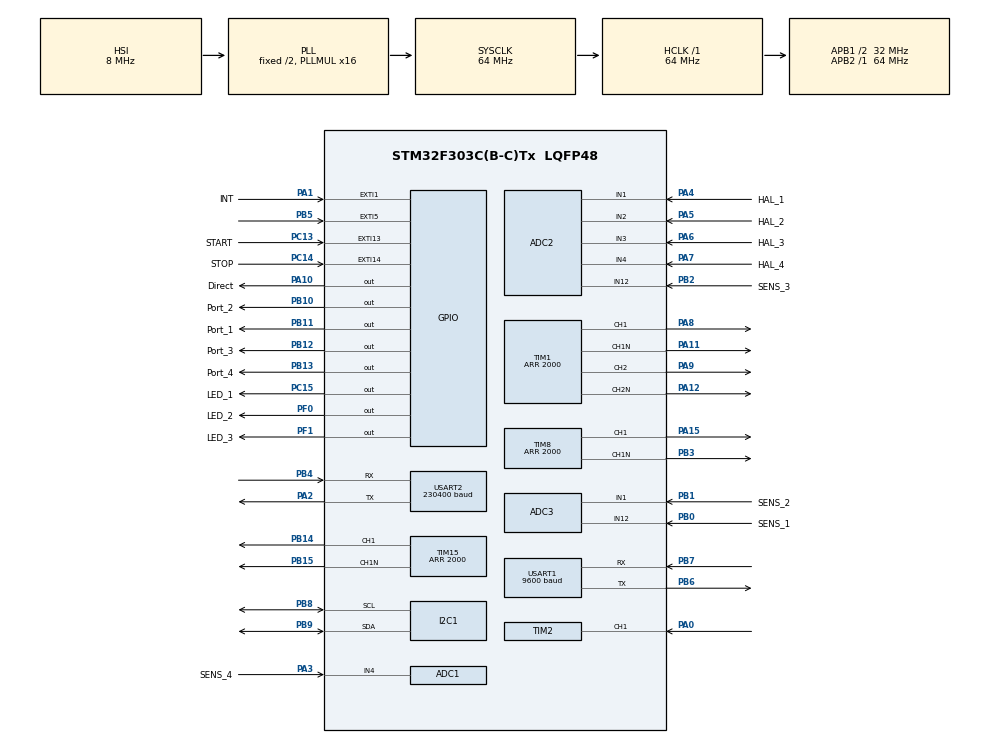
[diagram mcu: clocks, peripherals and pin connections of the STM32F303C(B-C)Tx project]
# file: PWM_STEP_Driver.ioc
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ADC1.Channel-3\#ChannelRegularConversion=ADC_CHANNEL_4
ADC1.ContinuousConvMode=DISABLE
ADC1.EnableInjectedConversion=DISABLE
ADC1.EnableRegularConversion=ENABLE
ADC1.NbrOfConversionFlag=1
ADC1.Offset-3\#ChannelRegularConversion=0
ADC1.OffsetNumber-3\#ChannelRegularConversion=ADC_OFFSET_NONE
ADC1.Rank-3\#ChannelRegularConversion=1
ADC1.SamplingTime-3\#ChannelRegularConversion=ADC_SAMPLETIME_4CYCLES_5
ADC1.SamplingTimeOPAMP-3\#ChannelRegularConversion=ADC_SAMPLETIME_61CYCLES_5
ADC1.master=1
ADC2.Channel-0\#ChannelRegularConversion=ADC_CHANNEL_1
ADC2.Channel-1\#ChannelRegularConversion=ADC_CHANNEL_2
ADC2.Channel-2\#ChannelRegularConversion=ADC_CHANNEL_3
ADC2.Channel-3\#ChannelRegularConversion=ADC_CHANNEL_4
ADC2.Channel-5\#ChannelRegularConversion=ADC_CHANNEL_12
ADC2.ContinuousConvMode=ENABLE
ADC2.EnableInjectedConversion=DISABLE
ADC2.NbrOfConversion=5
ADC2.NbrOfConversionFlag=1
ADC2.Offset-0\#ChannelRegularConversion=0
ADC2.Offset-1\#ChannelRegularConversion=0
ADC2.Offset-2\#ChannelRegularConversion=0
ADC2.Offset-3\#ChannelRegularConversion=0
ADC2.Offset-5\#ChannelRegularConversion=0
ADC2.OffsetNumber-0\#ChannelRegularConversion=ADC_OFFSET_NONE
ADC2.OffsetNumber-1\#ChannelRegularConversion=ADC_OFFSET_NONE
ADC2.OffsetNumber-2\#ChannelRegularConversion=ADC_OFFSET_NONE
ADC2.OffsetNumber-3\#ChannelRegularConversion=ADC_OFFSET_NONE
ADC2.OffsetNumber-5\#ChannelRegularConversion=ADC_OFFSET_NONE
ADC2.Rank-0\#ChannelRegularConversion=1
ADC2.Rank-1\#ChannelRegularConversion=2
ADC2.Rank-2\#ChannelRegularConversion=3
ADC2.Rank-3\#ChannelRegularConversion=4
ADC2.Rank-5\#ChannelRegularConversion=5
ADC2.SamplingTime-0\#ChannelRegularConversion=ADC_SAMPLETIME_4CYCLES_5
ADC2.SamplingTime-1\#ChannelRegularConversion=ADC_SAMPLETIME_4CYCLES_5
ADC2.SamplingTime-2\#ChannelRegularConversion=ADC_SAMPLETIME_4CYCLES_5
ADC2.SamplingTime-3\#ChannelRegularConversion=ADC_SAMPLETIME_4CYCLES_5
ADC2.SamplingTime-5\#ChannelRegularConversion=ADC_SAMPLETIME_4CYCLES_5
ADC2.SequencerNbRanks=5
ADC3.Channel-6\#ChannelRegularConversion=ADC_CHANNEL_1
ADC3.DiscontinuousConvMode=DISABLE
ADC3.EnableInjectedConversion=DISABLE
ADC3.EnableRegularConversion=ENABLE
ADC3.NbrOfConversion=1
ADC3.NbrOfConversionFlag=1
ADC3.Offset-6\#ChannelRegularConversion=0
ADC3.OffsetNumber-6\#ChannelRegularConversion=ADC_OFFSET_NONE
ADC3.Rank-6\#ChannelRegularConversion=1
ADC3.Rank1_Channel=ADC_CHANNEL_1
ADC3.Rank2_Channel=ADC_CHANNEL_1
ADC3.SamplingTime-6\#ChannelRegularConversion=ADC_SAMPLETIME_4CYCLES_5
ADC3.SequencerNbRanks=0
ADC3.master=1
Dma.ADC2.0.Direction=DMA_PERIPH_TO_MEMORY
Dma.ADC2.0.Instance=DMA2_Channel1
Dma.ADC2.0.MemDataAlignment=DMA_MDATAALIGN_HALFWORD
Dma.ADC2.0.MemInc=DMA_MINC_ENABLE
Dma.ADC2.0.Mode=DMA_NORMAL
Dma.ADC2.0.PeriphDataAlignment=DMA_PDATAALIGN_HALFWORD
Dma.ADC2.0.PeriphInc=DMA_PINC_DISABLE
Dma.ADC2.0.Priority=DMA_PRIORITY_LOW
Dma.Request0=ADC2
Dma.Request1=USART2_RX
Dma.Request2=USART2_TX
Dma.USART2_RX.1.Direction=DMA_PERIPH_TO_MEMORY
Dma.USART2_RX.1.Instance=DMA1_Channel6
Dma.USART2_RX.1.MemDataAlignment=DMA_MDATAALIGN_BYTE
Dma.USART2_RX.1.MemInc=DMA_MINC_ENABLE
Dma.USART2_RX.1.Mode=DMA_NORMAL
Dma.USART2_RX.1.PeriphDataAlignment=DMA_PDATAALIGN_BYTE
Dma.USART2_RX.1.PeriphInc=DMA_PINC_DISABLE
Dma.USART2_RX.1.Priority=DMA_PRIORITY_HIGH
Dma.USART2_TX.2.Direction=DMA_MEMORY_TO_PERIPH
Dma.USART2_TX.2.Instance=DMA1_Channel7
Dma.USART2_TX.2.MemDataAlignment=DMA_MDATAALIGN_BYTE
Dma.USART2_TX.2.MemInc=DMA_MINC_ENABLE
Dma.USART2_TX.2.Mode=DMA_NORMAL
Dma.USART2_TX.2.PeriphDataAlignment=DMA_PDATAALIGN_BYTE
Dma.USART2_TX.2.PeriphInc=DMA_PINC_DISABLE
Dma.USART2_TX.2.Priority=DMA_PRIORITY_LOW
I2C1.OwnAddress=0x12
Mcu.Family=STM32F3
Mcu.Name=STM32F303C(B-C)Tx
Mcu.Package=LQFP48
NVIC.ADC1_2_IRQn=true\:2\:0\:true\:false\:true\:true\:true\:true
NVIC.DMA1_Channel6_IRQn=true\:0\:0\:false\:false\:true\:false\:true\:true
NVIC.DMA1_Channel7_IRQn=true\:0\:0\:false\:false\:true\:false\:true\:true
NVIC.DMA2_Channel1_IRQn=true\:0\:0\:false\:false\:true\:false\:true\:true
NVIC.EXTI15_10_IRQn=true\:3\:0\:true\:false\:true\:true\:true\:true
NVIC.EXTI1_IRQn=true\:0\:0\:false\:false\:true\:true\:true\:true
NVIC.EXTI9_5_IRQn=true\:1\:0\:true\:false\:true\:true\:true\:true
NVIC.I2C1_ER_IRQn=true\:0\:0\:false\:false\:true\:true\:true\:true
NVIC.I2C1_EV_IRQn=true\:0\:0\:false\:false\:true\:true\:true\:true
NVIC.PriorityGroup=NVIC_PRIORITYGROUP_4
NVIC.RCC_IRQn=true\:0\:0\:false\:false\:true\:true\:false\:true
NVIC.TIM2_IRQn=true\:0\:0\:false\:false\:true\:true\:true\:true
NVIC.USART2_IRQn=true\:1\:0\:true\:false\:true\:true\:true\:true
PA0.Signal=S_TIM2_CH1_ETR
PA1.GPIO_Label=INT
PA1.GPIO_ModeDefaultEXTI=GPIO_MODE_IT_RISING_FALLING
PA1.Signal=GPXTI1
PA10.GPIO_Label=Direct
PA10.Signal=GPIO_Output
PA11.Mode=PWM Generation1 CH1 CH1N
PA11.Signal=TIM1_CH1N
PA12.Mode=PWM Generation2 CH2 CH2N
PA12.Signal=TIM1_CH2N
PA13.Mode=Serial_Wire
PA13.Signal=SYS_JTMS-SWDIO
PA14.Mode=Serial_Wire
PA14.Signal=SYS_JTCK-SWCLK
PA15.Signal=S_TIM8_CH1
PA2.Mode=Asynchronous
PA2.Signal=USART2_TX
PA3.GPIO_Label=SENS_4
PA3.Mode=IN4-Single-Ended
PA3.Signal=ADC1_IN4
PA4.GPIO_Label=HAL_1
PA4.Mode=IN1-Single-Ended
PA4.Signal=ADC2_IN1
PA5.GPIO_Label=HAL_2
PA5.Mode=IN2-Single-Ended
PA5.Signal=ADC2_IN2
PA6.GPIO_Label=HAL_3
PA6.Mode=IN3-Single-Ended
PA6.Signal=ADC2_IN3
PA7.GPIO_Label=HAL_4
PA7.Mode=IN4-Single-Ended
PA7.Signal=ADC2_IN4
PA8.Signal=S_TIM1_CH1
PA9.Signal=S_TIM1_CH2
PB0.GPIO_Label=SENS_1
PB0.Mode=IN12-Single-Ended
PB0.Signal=ADC3_IN12
PB1.GPIO_Label=SENS_2
PB1.Mode=IN1-Single-Ended
PB1.Signal=ADC3_IN1
PB10.GPIO_Label=Port_2
PB10.Signal=GPIO_Output
PB11.GPIO_Label=Port_1
PB11.Signal=GPIO_Output
PB12.GPIO_Label=Port_3
PB12.Signal=GPIO_Output
PB13.GPIO_Label=Port_4
PB13.Signal=GPIO_Output
PB14.Signal=S_TIM15_CH1
PB15.Mode=PWM Generation1 CH1 CH1N
PB15.Signal=TIM15_CH1N
PB2.GPIO_Label=SENS_3
PB2.Mode=IN12-Single-Ended
PB2.Signal=ADC2_IN12
PB3.Mode=PWM Generation1 CH1 CH1N
PB3.Signal=TIM8_CH1N
PB4.Mode=Asynchronous
PB4.Signal=USART2_RX
PB5.GPIO_ModeDefaultEXTI=GPIO_MODE_IT_RISING_FALLING
PB5.Signal=GPXTI5
PB6.Mode=Asynchronous
PB6.Signal=USART1_TX
PB7.Mode=Asynchronous
PB7.Signal=USART1_RX
PB8.GPIO_Pu=GPIO_PULLUP
PB8.Mode=I2C
PB8.Signal=I2C1_SCL
PB9.GPIO_Pu=GPIO_PULLUP
PB9.Mode=I2C
PB9.Signal=I2C1_SDA
PC13.GPIO_Label=START
PC13.GPIO_ModeDefaultEXTI=GPIO_MODE_IT_RISING_FALLING
PC13.Signal=GPXTI13
PC14-OSC32_IN.GPIO_Label=STOP
PC14-OSC32_IN.GPIO_ModeDefaultEXTI=GPIO_MODE_IT_RISING_FALLING
PC14-OSC32_IN.Signal=GPXTI14
PC15-OSC32_OUT.GPIO_Label=LED_1
PC15-OSC32_OUT.PinState=GPIO_PIN_RESET
PC15-OSC32_OUT.Signal=GPIO_Output
PF0-OSC_IN.GPIO_Label=LED_2
PF0-OSC_IN.PinState=GPIO_PIN_RESET
PF0-OSC_IN.Signal=GPIO_Output
PF1-OSC_OUT.GPIO_Label=LED_3
PF1-OSC_OUT.PinState=GPIO_PIN_RESET
PF1-OSC_OUT.Signal=GPIO_Output
ProjectManager.HeapSize=0x200
ProjectManager.StackSize=0x400
ProjectManager.TargetToolchain=STM32CubeIDE
RCC.AHBFreq_Value=64000000
RCC.APB1CLKDivider=RCC_HCLK_DIV2
RCC.APB1Freq_Value=32000000
RCC.APB1TimFreq_Value=64000000
RCC.APB2Freq_Value=64000000
RCC.APB2TimFreq_Value=64000000
RCC.CortexFreq_Value=64000000
RCC.HCLKFreq_Value=64000000
RCC.HSE_VALUE=8000000
RCC.HSI_VALUE=8000000
RCC.LSE_VALUE=32768
RCC.PLLMUL=RCC_PLL_MUL16
RCC.SYSCLKFreq_VALUE=64000000
RCC.SYSCLKSourceVirtual=RCC_SYSCLKSOURCE_PLLCLK
RCC.USBFreq_Value=64000000
RTC.Hours=9
RTC.Month=RTC_MONTH_JUNE
RTC.SynchPrediv=311
SH.S_TIM15_CH1.0=TIM15_CH1,PWM Generation1 CH1 CH1N
SH.S_TIM1_CH1.0=TIM1_CH1,PWM Generation1 CH1 CH1N
SH.S_TIM1_CH2.0=TIM1_CH2,PWM Generation2 CH2 CH2N
SH.S_TIM2_CH1_ETR.0=TIM2_CH1,Input_Capture1_from_TI1
SH.S_TIM8_CH1.0=TIM8_CH1,PWM Generation1 CH1 CH1N
TIM1.AutoReloadPreload=TIM_AUTORELOAD_PRELOAD_ENABLE
TIM1.Channel-PWM\ Generation1\ CH1\ CH1N=TIM_CHANNEL_1
TIM1.Channel-PWM\ Generation2\ CH2\ CH2N=TIM_CHANNEL_2
TIM1.DeadTime=100
TIM1.OCFastMode_PWM-PWM\ Generation1\ CH1\ CH1N=TIM_OCFAST_ENABLE
TIM1.OCFastMode_PWM-PWM\ Generation2\ CH2\ CH2N=TIM_OCFAST_ENABLE
TIM1.OCMode_PWM-PWM\ Generation1\ CH1\ CH1N=TIM_OCMODE_PWM1
TIM1.OCMode_PWM-PWM\ Generation2\ CH2\ CH2N=TIM_OCMODE_PWM1
TIM1.Period=2000
TIM1.Pulse-PWM\ Generation1\ CH1\ CH1N=1000
TIM1.Pulse-PWM\ Generation2\ CH2\ CH2N=1000
TIM1.RepetitionCounter=0
TIM15.AutoReloadPreload=TIM_AUTORELOAD_PRELOAD_ENABLE
TIM15.Channel-PWM\ Generation1\ CH1\ CH1N=TIM_CHANNEL_1
TIM15.DeadTime=100
TIM15.Period=2000
TIM15.Pulse-PWM\ Generation1\ CH1\ CH1N=1000
TIM2.Channel-Input_Capture1_from_TI1=TIM_CHANNEL_1
TIM2.Channel-Input_Capture2_from_TI1_63=TIM_CHANNEL_2
TIM2.ICFilter_CH1=12
TIM2.ICPolarity_CH2=TIM_INPUTCHANNELPOLARITY_FALLING
TIM2.Period=64000000
TIM2.Prescaler=0
TIM3.AutoReloadPreload=TIM_AUTORELOAD_PRELOAD_ENABLE
TIM3.TIM_MasterSlaveMode=TIM_MASTERSLAVEMODE_DISABLE
TIM8.AutoReloadPreload=TIM_AUTORELOAD_PRELOAD_ENABLE
TIM8.Channel-PWM\ Generation1\ CH1\ CH1N=TIM_CHANNEL_1
TIM8.DeadTime=100
TIM8.OCMode_PWM-PWM\ Generation1\ CH1\ CH1N=TIM_OCMODE_PWM1
TIM8.Period=2000
TIM8.Pulse-PWM\ Generation1\ CH1\ CH1N=1000
TIM8.RepetitionCounter=0
USART1.BaudRate=9600
USART1.VirtualMode-Asynchronous=VM_ASYNC
USART2.BaudRate=230400
USART2.VirtualMode-Asynchronous=VM_ASYNC
VP_RTC_VS_RTC_Activate.Mode=RTC_Enabled
VP_RTC_VS_RTC_Calendar.Mode=RTC_Calendar
VP_TIM15_VS_ClockSourceINT.Mode=Internal
VP_TIM1_VS_ClockSourceINT.Mode=Internal
VP_TIM2_VS_ClockSourceINT.Mode=Internal
VP_TIM2_VS_indirect_ch1.Mode=Input_Capture2_from_TI1_63
VP_TIM3_VS_ClockSourceINT.Mode=Internal
VP_TIM8_VS_ClockSourceINT.Mode=Internal
board=custom

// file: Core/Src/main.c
/* USER CODE BEGIN Header */
/**
  ******************************************************************************
  * @file           : main.c
  * @brief          : Main program body
  ******************************************************************************
  * @attention
  *
  * Copyright (c) 2023 STMicroelectronics.
  * All rights reserved.
  *
  * This software is licensed under terms that can be found in the LICENSE file
  * in the root directory of this software component.
  * If no LICENSE file comes with this software, it is provided AS-IS.
  *
  ******************************************************************************
  */
/* USER CODE END Header */
#include "main.h"

/* USER CODE BEGIN Includes */
#include "string.h"
#include "stdint.h"
#include "stdio.h"
#include "math.h"
#include "modbusDevice.h"
#include "modbusSlave.h"

/* USER CODE END Includes */

/* USER CODE BEGIN PD */
#define TX_2    HAL_GPIO_WritePin(GPIOA, GPIO_PIN_10,GPIO_PIN_SET);
#define RX_2    HAL_GPIO_WritePin(GPIOA, GPIO_PIN_10,GPIO_PIN_RESET);

#define PORT1_ON    HAL_GPIO_WritePin(GPIOB, GPIO_PIN_11,GPIO_PIN_SET);
#define PORT1_OFF   HAL_GPIO_WritePin(GPIOB, GPIO_PIN_11,GPIO_PIN_RESET);

#define PORT2_ON    HAL_GPIO_WritePin(GPIOB, GPIO_PIN_10,GPIO_PIN_SET);
#define PORT2_OFF   HAL_GPIO_WritePin(GPIOB, GPIO_PIN_10,GPIO_PIN_RESET);

#define PORT3_ON    HAL_GPIO_WritePin(GPIOB, GPIO_PIN_12,GPIO_PIN_SET);
#define PORT3_OFF   HAL_GPIO_WritePin(GPIOB, GPIO_PIN_12,GPIO_PIN_RESET);

#define PORT4_ON    HAL_GPIO_WritePin(GPIOB, GPIO_PIN_13,GPIO_PIN_SET);
#define PORT4_OFF   HAL_GPIO_WritePin(GPIOB, GPIO_PIN_13,GPIO_PIN_RESET);
#define LED_1_ON    HAL_GPIO_WritePin(GPIOC, GPIO_PIN_15,GPIO_PIN_SET);
#define LED_1_OFF   HAL_GPIO_WritePin(GPIOC, GPIO_PIN_15,GPIO_PIN_RESET);
#define LED_2_ON    HAL_GPIO_WritePin(GPIOF, GPIO_PIN_0,GPIO_PIN_SET);
#define LED_2_OFF   HAL_GPIO_WritePin(GPIOF, GPIO_PIN_0,GPIO_PIN_RESET);

#define LED_3_ON    HAL_GPIO_WritePin(GPIOF, GPIO_PIN_1,GPIO_PIN_SET);
#define LED_3_OFF   HAL_GPIO_WritePin(GPIOF, GPIO_PIN_1,GPIO_PIN_RESET);

#define CLEAR HAL_GPIO_ReadPin(GPIOB, GPIO_PIN_5)

//////////////////////////////////////////////////////////////////////////////////////////////

#define LCD_ADDR (0x27 << 1)       // адрес дисплея, сдвинутый на 1 бит влево (HAL работает с I2C-адресами, сдвинутыми на 1 бит влево)

#define PIN_RS    (1 << 0)         // если на ножке 0, данные воспринимаются как команда, если 1 - как символы для вывода
#define PIN_EN    (1 << 2)         // бит, по изменению сост. которого считывается информация
#define BACKLIGHT (1 << 3)         // управление подсветкой

#define LCD_DELAY_MS 5             // пауза перед высвечиванием символа

//////////////////////////////////////////////////////////////////////////////////////////////

#define I2C_ADDR 0x27 // I2C address of the PCF8574
#define RS_BIT 0 // Register select bit
#define EN_BIT 2 // Enable bit
#define BL_BIT 3 // Backlight bit
#define D4_BIT 4 // Data 4 bit
#define D5_BIT 5 // Data 5 bit
#define D6_BIT 6 // Data 6 bit
#define D7_BIT 7 // Data 7 bit

#define LCD_ROWS 4 // Number of rows on the LCD
#define LCD_COLS 20 // Number of columns on the LCD

#define N 20

#define I2C_SLAVE_ADDRESS   0x2D
/////////////////////////////////////////////////////////////

/* USER CODE END PD */

ADC_HandleTypeDef hadc1;
ADC_HandleTypeDef hadc2;
ADC_HandleTypeDef hadc3;
DMA_HandleTypeDef hdma_adc2;

I2C_HandleTypeDef hi2c1;

RTC_HandleTypeDef hrtc;

TIM_HandleTypeDef htim1;
TIM_HandleTypeDef htim2;
TIM_HandleTypeDef htim3;
TIM_HandleTypeDef htim8;
TIM_HandleTypeDef htim15;

UART_HandleTypeDef huart1;
UART_HandleTypeDef huart2;
DMA_HandleTypeDef hdma_usart2_rx;
DMA_HandleTypeDef hdma_usart2_tx;

/* USER CODE BEGIN PV */
char str[112]={0, };
uint16_t count=0;
static uint16_t current[4]={0, };
static uint16_t hall_sens[5]={0, };
uint16_t pwm[]={10,10,10,10 };
uint8_t TxData[6] = {0, };
//uint16_t slaveADDR = 0x12<<1;

uint16_t limit=500;

uint16_t pwm_n=0;

volatile uint16_t pwm_cmd=0;
uint8_t pwm_tgr=0;
volatile uint8_t flag = 0;

 int period=0;
 uint16_t pulseWidth=0;
 uint16_t rpm=0;
 uint16_t f=0;
 uint8_t backlight_state = 1;
 uint8_t adc_count=0;
 uint8_t adc_filter[]={0,0,0,0};
 uint8_t page_num=0;
 uint8_t page_flag=0;
 uint16_t current_avg=0;
 uint16_t current_sum=0;
 uint8_t min=0;
 uint8_t hour=0;
 uint8_t sec=0;
 uint8_t status=0;
 uint16_t current_dc=5;
 uint16_t voltage_dc=25;

 I2C_HandleTypeDef* i2cMasterHandler = &hi2c1;

 uint8_t rxFrame[16];
 uint8_t txFrame[255];
 uint8_t SLAVE_ID=1;
 uint16_t data_reg[16]={0,};
 uint16_t rcv_data_reg[16]={0,};

 RTC_TimeTypeDef sTime = {0};
 RTC_DateTypeDef sDate = {0};

/* USER CODE END PV */

void SystemClock_Config(void);
static void MX_GPIO_Init(void);
static void MX_DMA_Init(void);
static void MX_ADC2_Init(void);
static void MX_TIM1_Init(void);
static void MX_TIM2_Init(void);
static void MX_USART1_UART_Init(void);
static void MX_USART2_UART_Init(void);
static void MX_TIM8_Init(void);
static void MX_I2C1_Init(void);
static void MX_RTC_Init(void);
static void MX_TIM15_Init(void);
static void MX_ADC1_Init(void);
static void MX_ADC3_Init(void);
static void MX_TIM3_Init(void);
/* USER CODE BEGIN PFP */

void ADC_reset_ch(void){

	ADC_ChannelConfTypeDef sConfig = {0};

		              sConfig.Channel = ADC_CHANNEL_1;
		              sConfig.Rank = 0;
		              HAL_ADC_ConfigChannel(&hadc3, &sConfig);
		              sConfig.Channel = ADC_CHANNEL_2;
		              sConfig.Rank =0;
		              HAL_ADC_ConfigChannel(&hadc3, &sConfig);
}

void ADC_Select_CH1 (void)
	     {
	     	ADC_ChannelConfTypeDef sConfig = {0};
	     	  /** Configure for the selected ADC regular channel its corresponding rank in the sequencer and its sample time.
	     	  */
	     	  sConfig.Channel = ADC_CHANNEL_1;
	     	  sConfig.Rank = 1;
	     	  sConfig.SamplingTime = ADC_SAMPLETIME_7CYCLES_5;
	     	  HAL_ADC_ConfigChannel(&hadc3, &sConfig);
	     }

void ADC_Select_CH12 (void)
	     {
	     	ADC_ChannelConfTypeDef sConfig = {0};
	     	  /** Configure for the selected ADC regular channel its corresponding rank in the sequencer and its sample time.
	     	  */
	     	  sConfig.Channel = ADC_CHANNEL_12;
	     	  sConfig.Rank = 1;
	     	  sConfig.SamplingTime = ADC_SAMPLETIME_7CYCLES_5;
	     	  HAL_ADC_ConfigChannel(&hadc3, &sConfig);
	     }

uint16_t ADC_read_1(void)

	  {
//	ADC_reset_ch();
	ADC_Select_CH1 ();
	current[1]=0;
	HAL_ADC_Start(&hadc3);

	 		  HAL_ADC_PollForConversion(&hadc3, 100);
	 		  current[1] = HAL_ADC_GetValue(&hadc3);
	 		  HAL_ADC_Stop(&hadc3);

	 		  return current[1];
	  }

uint16_t ADC_read_12(void)

	  {
//	ADC_reset_ch();
	ADC_Select_CH12 ();
	current[0]=0;
	HAL_ADC_Start(&hadc3);

	 		  HAL_ADC_PollForConversion(&hadc3, 100);
	 		  current[0] = HAL_ADC_GetValue(&hadc3);
	 		  HAL_ADC_Stop(&hadc3);

	 		  return current[0];
	  }

void PWM_correction(void){

for(uint8_t i=0;i<4;i++){

	pwm[i]=pwm_cmd;

	if((current[i]>=limit)&&(pwm[i]>=10)){
	pwm[i]=pwm[i]-10;
    LED_2_ON;
	}

	//TxData[0]=pwm_cmd>>8;
	//TxData[1]=pwm_cmd&0xff;

	if(current[i]>=3800){

		            HAL_TIM_PWM_Stop(&htim1, TIM_CHANNEL_1);
		            HAL_TIM_PWM_Stop(&htim1, TIM_CHANNEL_2);
		            HAL_TIM_PWM_Stop(&htim8, TIM_CHANNEL_1);
		            HAL_TIM_PWM_Stop(&htim15, TIM_CHANNEL_1);

		            HAL_TIMEx_PWMN_Stop(&htim1, TIM_CHANNEL_1);
		            HAL_TIMEx_PWMN_Stop(&htim1, TIM_CHANNEL_2);
		            HAL_TIMEx_PWMN_Stop(&htim8, TIM_CHANNEL_1);
		            HAL_TIMEx_PWMN_Stop(&htim15, TIM_CHANNEL_1);

		            pwm[0]=10;
		            pwm[1]=10;
		            pwm[2]=10;
		            pwm[3]=10;

		            LED_2_ON;}

	if((pwm[i]>=10)&&(current[i]<=10)){LED_2_OFF;}

}
pwm_n=(pwm[0]+pwm[1]+pwm[2]+pwm[3])/4;
}
////////////////////////////////////////////////////////////////////////////////////////////

void I2C_send(uint8_t data, uint8_t flags)
{
	HAL_StatusTypeDef res;
	 // бесконечный цикл
        for(;;) {
                // проверяем, готово ли устройство по адресу lcd_addr для связи
	        res = HAL_I2C_IsDeviceReady(&hi2c1, LCD_ADDR, 1, HAL_MAX_DELAY);
	         // если да, то выходим из бесконечного цикла
                if(res == HAL_OK) break;
	    }
        // операция �? с 1111 0000 приводит к обнулению бит с 0 по 3, остаются биты с 4 по 7
	uint8_t up = data & 0xF0;
        // то же самое, но data сдвигается на 4 бита влево
        uint8_t lo = (data << 4) & 0xF0;

	uint8_t data_arr[4];
         // 4-7 биты содержат информацию, биты 0-3 настраивают работу дисплея
	data_arr[0] = up|flags|BACKLIGHT|PIN_EN;
         // дублирование сигнала, на выводе Е в этот раз 0
	data_arr[1] = up|flags|BACKLIGHT;
	data_arr[2] = lo|flags|BACKLIGHT|PIN_EN;
	data_arr[3] = lo|flags|BACKLIGHT;

	HAL_I2C_Master_Transmit(&hi2c1, LCD_ADDR, data_arr, sizeof(data_arr), HAL_MAX_DELAY);
	HAL_Delay(LCD_DELAY_MS);
}

void LCD_SendString(char *str)
{
    // *char по сути является строкой
	while(*str) {                                   // пока строчка не закончится
		I2C_send((uint8_t)(*str), 1);               // передача первого символа строки
        str++;                                      // сдвиг строки налево на 1 символ
    }
}

////////////////////////////////////////////////////////////////////////////////////////////

void lcd_write_nibble(uint8_t nibble, uint8_t rs) {
  uint8_t data = nibble << D4_BIT;
  data |= rs << RS_BIT;
  data |= backlight_state << BL_BIT; // Include backlight state in data
  data |= 1 << EN_BIT;
  HAL_I2C_Master_Transmit(&hi2c1, I2C_ADDR << 1, &data, 1, 100);
  HAL_Delay(1);
  data &= ~(1 << EN_BIT);
  HAL_I2C_Master_Transmit(&hi2c1, I2C_ADDR << 1, &data, 1, 100);
}

////////////////////////////////////////////////////////////////////////////////////////////

void lcd_send_cmd(uint8_t cmd) {
  uint8_t upper_nibble = cmd >> 4;
  uint8_t lower_nibble = cmd & 0x0F;
  lcd_write_nibble(upper_nibble, 0);
  lcd_write_nibble(lower_nibble, 0);
  if (cmd == 0x01 || cmd == 0x02) {
    HAL_Delay(2);
  }
}

//////////////////////////////////////////////////////////////////////////////////////////////

void lcd_send_data(uint8_t data) {
  uint8_t upper_nibble = data >> 4;
  uint8_t lower_nibble = data & 0x0F;
  lcd_write_nibble(upper_nibble, 1);
  lcd_write_nibble(lower_nibble, 1);
}

//////////////////////////////////////////////////////////////////////////////////////////////

void lcd_init() {
  HAL_Delay(50);
  lcd_write_nibble(0x03, 0);
  HAL_Delay(5);
  lcd_write_nibble(0x03, 0);
  HAL_Delay(1);
  lcd_write_nibble(0x03, 0);
  HAL_Delay(1);
  lcd_write_nibble(0x02, 0);
  lcd_send_cmd(0x28);
  lcd_send_cmd(0x0C);
  lcd_send_cmd(0x06);
  lcd_send_cmd(0x01);
  HAL_Delay(2);
}

//////////////////////////////////////////////////////////////////////////////////////////////

void lcd_write_string(char *str) {
  while (*str) {
    lcd_send_data(*str++);
  }
}
//////////////////////////////////////////////////////////////////////////

void lcd_set_cursor(uint8_t row, uint8_t column) {
    uint8_t address;
    switch (row) {
        case 1:
            address = 0x80;
            break;
        case 2:
            address = 0xC0;
            break;

        case 3:
            address = 0x94;
            break;
        case 4:
            address = 0xD4;
            break;

        default:
            address = 0x80;
    }
    address += column;
    lcd_send_cmd(0x80 | address);
}

//////////////////////////////////////////////////////////////////////////////////////////////////

void lcd_clear(void) {
	lcd_send_cmd(0x01);
    HAL_Delay(2);
}

//////////////////////////////////////////////////////////////////////////////////////////////////

void lcd_backlight(uint8_t state) {
  if (state) {
    backlight_state = 1;
  } else {
    backlight_state = 0;
  }
}

//////////////////////////////////////////////////////////////////////////////////////////////

int filter(int x)
  {
  static int n;
  static int m[N];
  static int y;
  y=y+(x-m[n]);
  m[n]=x;
  n=(n+1)%N;
  return y/N;
  }

//////////////////////////////////////////////////////////////////////////////////////////////
/*
void page(void){
	if((!CLEAR)&&(!page_flag)){
		LED_3_ON;
		page_flag=1;
        page_num++;
        lcd_clear();
	}

	if((CLEAR)&&(page_flag)){
			LED_3_OFF;

			 if(page_num>2){page_num=0;}
			 page_flag=0;

		}
}
*/
/////////////////////////////////////////////////////////////////////////////////////////////

void HAL_UARTEx_RxEventCallback(UART_HandleTypeDef *huart, uint16_t Size)
{
	if (huart->Instance == USART2)
	{

        //  LED_3_ON;
				 if (rxFrame[0] == SLAVE_ID) {

					  			 		uint8_t opCode = rxFrame[1];
					  			     switch (opCode) {
					  			       case READ_COILs:

					  			    	 break;
					  			       case  READ_INPUT_REGs:
					  			    	 handleReadHoldingRegs(&huart2,data_reg);

					  			    	   break;
					  			     case WRITE_SINGLE_REG:

					  			   					  			    //	 handleWriteSingleHandlingRegister (&huart2,data_reg);
					  			   					  			    	handleWriteMulyipleHandlingRegister (&huart2,rcv_data_reg);
					  			                                              pwm_cmd=rcv_data_reg[1];

					  			                                               break;

					  			       case WRITE_HOLDING_REGs:

					  			    	handleWriteMulyipleHandlingRegister (&huart2,rcv_data_reg);
					  			    	 pwm_cmd=rcv_data_reg[1];
					  			    	 limit=rcv_data_reg[2];
					  			    	hour=(rcv_data_reg[3]>>8) & 0xff;
					  			        min= rcv_data_reg[3] & 0xff;
					  			    	sec=rcv_data_reg[4];

                                            break;

					  			       default:
					  			 				break;
					  			     }

					  			 }

		/* start the DMA again */

			//	 for(uint8_t i=0;i<sizeof(rxFrame);)
			//	 {           rxFrame[i]=0;i++;}

		HAL_UARTEx_ReceiveToIdle_DMA(&huart2, (uint8_t *) rxFrame,sizeof(rxFrame));
		__HAL_DMA_DISABLE_IT(&hdma_usart2_rx, DMA_IT_HT);

	}
}

/* USER CODE END PFP */

/* USER CODE BEGIN 0 */

static void I2C_Init(void)
{

	//I2C1 GPIO

	GPIOB->MODER |= ( GPIO_MODER_MODER9_1 | GPIO_MODER_MODER8_1 );

	GPIOB->OTYPER |= ( GPIO_OTYPER_OT_9 | GPIO_OTYPER_OT_8 );
	GPIOB->PUPDR |= (GPIO_PUPDR_PUPDR8_1|GPIO_PUPDR_PUPDR9_1);

	  SET_BIT(RCC->AHBENR,RCC_AHBENR_GPIOBEN);
	  SET_BIT(RCC->APB1ENR, RCC_APB1ENR_I2C1EN);

	  GPIOB->AFR[1] |= (4<<0) | (4<<4);

	  I2C1->CR1 |= (1<<15);  // reset the I2C
	  I2C1->CR1 &= ~(1<<15);  // Normal operation
}

void lcd_init();
void lcd_write_nibble(uint8_t nibble, uint8_t rs);
void lcd_send_cmd(uint8_t cmd);
void lcd_send_data(uint8_t data);
void lcd_write_string(char *str);
void lcd_set_cursor(uint8_t row, uint8_t column);
void lcd_clear(void);
void lcd_backlight(uint8_t state);

int filter(int x);
void page(void);
/* USER CODE END 0 */

int main(void)
{

  /* MCU Configuration--------------------------------------------------------*/

  /* Reset of all peripherals, Initializes the Flash interface and the Systick. */
  HAL_Init();

  /* Configure the system clock */
  SystemClock_Config();

  /* Initialize all configured peripherals */
  MX_GPIO_Init();
  MX_DMA_Init();
  MX_ADC2_Init();
  MX_TIM1_Init();
  MX_TIM2_Init();
  MX_USART1_UART_Init();
  MX_USART2_UART_Init();
  MX_TIM8_Init();
  MX_I2C1_Init();
  MX_RTC_Init();
  MX_TIM15_Init();
  MX_ADC1_Init();
  MX_ADC3_Init();
  MX_TIM3_Init();
  /* USER CODE BEGIN 2 */
  LED_2_ON;
	TX_2;

 TIM1->CCR1=pwm[0];
 TIM1->CCR2=pwm[1];
 TIM8->CCR1=pwm[2];
 TIM15->CCR1=pwm[3];

  HAL_TIM_PWM_Start(&htim1, TIM_CHANNEL_1);
  HAL_TIM_PWM_Start(&htim1, TIM_CHANNEL_2);
  HAL_TIM_PWM_Start(&htim8, TIM_CHANNEL_1);
  HAL_TIM_PWM_Start(&htim15, TIM_CHANNEL_1);

//  HAL_TIMEx_PWMN_Start(&htim1, TIM_CHANNEL_1);
//  HAL_TIMEx_PWMN_Start(&htim1, TIM_CHANNEL_2);
//  HAL_TIMEx_PWMN_Start(&htim8, TIM_CHANNEL_1);
//  HAL_TIMEx_PWMN_Start(&htim15, TIM_CHANNEL_1);

  HAL_TIM_IC_Start_IT(&htim2, TIM_CHANNEL_1);
  HAL_TIM_IC_Start_IT(&htim2, TIM_CHANNEL_2);

  PORT1_ON;
  PORT2_ON;
  PORT3_ON;
  PORT4_ON;

  HAL_ADCEx_Calibration_Start(&hadc2,5);
  HAL_ADCEx_Calibration_Start(&hadc1,4);
  HAL_ADCEx_Calibration_Start(&hadc3,2);

  flag=1;

  HAL_Delay(100);

  I2C_Init();

  lcd_init();
  lcd_clear();
    char *text = " ";
    char int_to_str[10];

  //   LED_2_OFF;

      I2C_send(0b00110000,0);   // 8ми битный интерфейс
      I2C_send(0b00000010,0);   // установка курсора в начале строки
      I2C_send(0b00001100,0);   // нормальный режим работы
      I2C_send(0b00000001,0);   // очистка дисплея

  	sprintf(int_to_str, "RPM-%05d t/min     ",rpm);
  				 	  		lcd_set_cursor(1, 0);
  				 	  	    lcd_write_string(int_to_str);

     HAL_ADC_Start_DMA(&hadc2, (uint16_t*)hall_sens, 5);
     HAL_UARTEx_ReceiveToIdle_DMA(&huart2, rxFrame, 16);
        __HAL_DMA_DISABLE_IT(&hdma_usart2_rx, DMA_IT_HT);
       RX_2;
      LED_2_OFF;
  RX_2;
  /* USER CODE END 2 */

  /* Infinite loop */
  /* USER CODE BEGIN WHILE */
  while (1)
  {

	  if(flag==1){
		  HAL_ADC_Stop_DMA(&hadc2);
		  current[2]=hall_sens[4];
		  HAL_ADC_Start(&hadc1);
		 	  		  	 HAL_ADC_PollForConversion(&hadc1, 100);
		 	  		     current[3]=0;
		 	  		  	 current[3]=HAL_ADC_GetValue(&hadc1);
		 	  		  	 HAL_ADC_Stop(&hadc1);

		 	  		  ADC_read_1();
		 	  		  ADC_read_12();

		 	  data_reg[0]=current[0];
		 	  data_reg[1]=current[1];
		 	  data_reg[2]=current[2];
		 	  data_reg[3]=current[3];
		 	  data_reg[4]=pwm[0];
		 	  data_reg[5]=pwm[1];
		 	  data_reg[6]=pwm[2];
		 	  data_reg[7]=pwm[3];
		 	  data_reg[8]=rpm;
		 	  data_reg[9]=f;
		 	  data_reg[10]=limit;
		 	  data_reg[11]=SLAVE_ID;
		 	  data_reg[12]=voltage_dc;
		 	  data_reg[13]=current_dc;

                current_avg=(current[0]+current[1]+current[2]+current[3])/4;
                current_sum=current[0]+current[1]+current[2]+current[3];
		 	  		  adc_count++;

		 	  	    adc_filter[0]= filter(current[0]);
		 	  		adc_filter[1]= filter(current[1]);
		 	  		adc_filter[2]= filter(current[2]);
		 	  		adc_filter[3]= filter(current[3]);

		 	  if(page_flag==1){lcd_clear();page_flag=0;}
		 	  	  if((page_num==0)&&(adc_count==20)){

				 	  		sprintf(int_to_str, "RPM-%05d t/min     ",rpm);
				 	  		lcd_set_cursor(1, 0);
				 	  	    lcd_write_string(int_to_str);

				 	  	    sprintf(int_to_str, "PWM_CMD-%05d/%03d%% ",pwm_n,pwm_n/20);
				 	  	 	lcd_set_cursor(2, 0);
				 	  	 	lcd_write_string(int_to_str);

				 	  	    sprintf(int_to_str, "ADC_avg-%05d ",current_avg);
				 	  	 	lcd_set_cursor(3, 0);
				 	  	 	lcd_write_string(int_to_str);

				 	    	sprintf(int_to_str, "F=%05dHz ",f);
				 	  	 	lcd_set_cursor(4, 0);
				 	  	 	lcd_write_string(int_to_str);	  }

		 	  	  if((page_num==2)&&(adc_count==22)){

		 	  		HAL_RTC_GetTime(&hrtc, &sTime, RTC_FORMAT_BIN); // RTC_FORMAT_BIN , RTC_FORMAT_BCD
		 	  	 HAL_RTC_GetDate(&hrtc, &sDate, RTC_FORMAT_BIN);

		 	  	                            sprintf(int_to_str, "START_TIME:%02d:%02d:%02d",hour,min,sec);
		 	  			 	  				lcd_set_cursor(1, 0);
		 	  			 	  			    lcd_write_string(int_to_str);

		 	  					 	  		sprintf(int_to_str, "TIME:%02d:%02d:%02d",sTime.Hours,sTime.Minutes,sTime.Seconds);
		 	  					 	  		lcd_set_cursor(2, 0);
		 	  					 	  	    lcd_write_string(int_to_str);

		 	  					 	  		sprintf(int_to_str, "ADC_filter:%02d",adc_filter[0]);
		 	  					 	  		lcd_set_cursor(3, 0);
		 	  					 	  	    lcd_write_string(int_to_str);

		 	  			 	  	  }

		 	  	  if(page_num==1){
		 	  	                 	if(adc_count==18){

		 	  				 	  		sprintf(int_to_str, "PWM-%02d%%/%04d",pwm[0]/20,pwm[0]);
		 	  				 	  		lcd_set_cursor(1, 0);
		 	  				 	  	    lcd_write_string(int_to_str);

		 	  				 	     	sprintf(int_to_str, "PWM-%02d%%/%04d",pwm[1]/20,pwm[1]);
		 	  				 	  	    lcd_set_cursor(2, 0);
		 	  				 	  	    lcd_write_string(int_to_str);

		 	  				 	  	    sprintf(int_to_str, "PWM-%02d%%/%04d",pwm[2]/20,pwm[2]);
		 	  				 	  	    lcd_set_cursor(3, 0);
		 	  				 	  		lcd_write_string(int_to_str);

		 	  				 	    	sprintf(int_to_str, "PWM-%02d%%/%04d",pwm[3]/20,pwm[3]);
		 	  				 	  	    lcd_set_cursor(4, 0);
		 	  				 	  		lcd_write_string(int_to_str);

		 	  				 	  		}

		 	  		if(adc_count==180){

		 	  			sprintf(int_to_str, "Adc-%03d",current[0]);
		 	  			lcd_set_cursor(1, 13);
		 	  		    lcd_write_string(int_to_str);

		 	  		    sprintf(int_to_str, "Adc-%03d",current[1]);
		 	  		 	lcd_set_cursor(2, 13);
		 	  		    lcd_write_string(int_to_str);

		 	  		    sprintf(int_to_str, "Adc-%03d",current[2]);
		 	  		    lcd_set_cursor(3, 13);
		 	  		    lcd_write_string(int_to_str);

		 	  	        sprintf(int_to_str, "Adc-%03d",current[3]);
		 	  	 		lcd_set_cursor(4, 13);
		 	  	 		lcd_write_string(int_to_str);

		 	  	    adc_count=0;
		 	  		}

		 	  	  }

		 // HAL_Delay(10);

	     PWM_correction();
	 // 	 page();
	  	 TIM1->CCR1=pwm[0];
	  	 TIM1->CCR2=pwm[1];
	  	 TIM8->CCR1=pwm[2];
	  	 TIM15->CCR1=pwm[3];
	  	 flag=0;
	  	 HAL_ADC_Start_DMA(&hadc2, (uint16_t*)hall_sens, 5);

	  }

    /* USER CODE END WHILE */

  }
}

void SystemClock_Config(void)
{
  RCC_OscInitTypeDef RCC_OscInitStruct = {0};
  RCC_ClkInitTypeDef RCC_ClkInitStruct = {0};
  RCC_PeriphCLKInitTypeDef PeriphClkInit = {0};

  /** Initializes the RCC Oscillators according to the specified parameters
  * in the RCC_OscInitTypeDef structure.
  */
  RCC_OscInitStruct.OscillatorType = RCC_OSCILLATORTYPE_HSI|RCC_OSCILLATORTYPE_LSI;
  RCC_OscInitStruct.HSIState = RCC_HSI_ON;
  RCC_OscInitStruct.HSICalibrationValue = RCC_HSICALIBRATION_DEFAULT;
  RCC_OscInitStruct.LSIState = RCC_LSI_ON;
  RCC_OscInitStruct.PLL.PLLState = RCC_PLL_ON;
  RCC_OscInitStruct.PLL.PLLSource = RCC_PLLSOURCE_HSI;
  RCC_OscInitStruct.PLL.PLLMUL = RCC_PLL_MUL16;
  if (HAL_RCC_OscConfig(&RCC_OscInitStruct) != HAL_OK)
  {
    Error_Handler();
  }

  /** Initializes the CPU, AHB and APB buses clocks
  */
  RCC_ClkInitStruct.ClockType = RCC_CLOCKTYPE_HCLK|RCC_CLOCKTYPE_SYSCLK
                              |RCC_CLOCKTYPE_PCLK1|RCC_CLOCKTYPE_PCLK2;
  RCC_ClkInitStruct.SYSCLKSource = RCC_SYSCLKSOURCE_PLLCLK;
  RCC_ClkInitStruct.AHBCLKDivider = RCC_SYSCLK_DIV1;
  RCC_ClkInitStruct.APB1CLKDivider = RCC_HCLK_DIV2;
  RCC_ClkInitStruct.APB2CLKDivider = RCC_HCLK_DIV1;

  if (HAL_RCC_ClockConfig(&RCC_ClkInitStruct, FLASH_LATENCY_2) != HAL_OK)
  {
    Error_Handler();
  }
  PeriphClkInit.PeriphClockSelection = RCC_PERIPHCLK_USART1|RCC_PERIPHCLK_USART2
                              |RCC_PERIPHCLK_I2C1|RCC_PERIPHCLK_RTC
                              |RCC_PERIPHCLK_TIM1|RCC_PERIPHCLK_TIM8
                              |RCC_PERIPHCLK_ADC12|RCC_PERIPHCLK_ADC34;
  PeriphClkInit.Usart1ClockSelection = RCC_USART1CLKSOURCE_PCLK2;
  PeriphClkInit.Usart2ClockSelection = RCC_USART2CLKSOURCE_PCLK1;
  PeriphClkInit.Adc12ClockSelection = RCC_ADC12PLLCLK_DIV1;
  PeriphClkInit.Adc34ClockSelection = RCC_ADC34PLLCLK_DIV1;
  PeriphClkInit.I2c1ClockSelection = RCC_I2C1CLKSOURCE_HSI;
  PeriphClkInit.RTCClockSelection = RCC_RTCCLKSOURCE_LSI;
  PeriphClkInit.Tim1ClockSelection = RCC_TIM1CLK_HCLK;
  PeriphClkInit.Tim8ClockSelection = RCC_TIM8CLK_HCLK;
  if (HAL_RCCEx_PeriphCLKConfig(&PeriphClkInit) != HAL_OK)
  {
    Error_Handler();
  }
}

static void MX_ADC1_Init(void)
{

  ADC_MultiModeTypeDef multimode = {0};
  ADC_ChannelConfTypeDef sConfig = {0};

  /** Common config
  */
  hadc1.Instance = ADC1;
  hadc1.Init.ClockPrescaler = ADC_CLOCK_ASYNC_DIV1;
  hadc1.Init.Resolution = ADC_RESOLUTION_12B;
  hadc1.Init.ScanConvMode = ADC_SCAN_DISABLE;
  hadc1.Init.ContinuousConvMode = DISABLE;
  hadc1.Init.DiscontinuousConvMode = DISABLE;
  hadc1.Init.ExternalTrigConvEdge = ADC_EXTERNALTRIGCONVEDGE_NONE;
  hadc1.Init.ExternalTrigConv = ADC_SOFTWARE_START;
  hadc1.Init.DataAlign = ADC_DATAALIGN_RIGHT;
  hadc1.Init.NbrOfConversion = 1;
  hadc1.Init.DMAContinuousRequests = DISABLE;
  hadc1.Init.EOCSelection = ADC_EOC_SINGLE_CONV;
  hadc1.Init.LowPowerAutoWait = DISABLE;
  hadc1.Init.Overrun = ADC_OVR_DATA_OVERWRITTEN;
  if (HAL_ADC_Init(&hadc1) != HAL_OK)
  {
    Error_Handler();
  }

  /** Configure the ADC multi-mode
  */
  multimode.Mode = ADC_MODE_INDEPENDENT;
  if (HAL_ADCEx_MultiModeConfigChannel(&hadc1, &multimode) != HAL_OK)
  {
    Error_Handler();
  }

  /** Configure Regular Channel
  */
  sConfig.Channel = ADC_CHANNEL_4;
  sConfig.Rank = ADC_REGULAR_RANK_1;
  sConfig.SingleDiff = ADC_SINGLE_ENDED;
  sConfig.SamplingTime = ADC_SAMPLETIME_4CYCLES_5;
  sConfig.OffsetNumber = ADC_OFFSET_NONE;
  sConfig.Offset = 0;
  if (HAL_ADC_ConfigChannel(&hadc1, &sConfig) != HAL_OK)
  {
    Error_Handler();
  }

}

static void MX_ADC2_Init(void)
{

  ADC_ChannelConfTypeDef sConfig = {0};

  /** Common config
  */
  hadc2.Instance = ADC2;
  hadc2.Init.ClockPrescaler = ADC_CLOCK_ASYNC_DIV1;
  hadc2.Init.Resolution = ADC_RESOLUTION_12B;
  hadc2.Init.ScanConvMode = ADC_SCAN_ENABLE;
  hadc2.Init.ContinuousConvMode = ENABLE;
  hadc2.Init.DiscontinuousConvMode = DISABLE;
  hadc2.Init.ExternalTrigConvEdge = ADC_EXTERNALTRIGCONVEDGE_NONE;
  hadc2.Init.ExternalTrigConv = ADC_SOFTWARE_START;
  hadc2.Init.DataAlign = ADC_DATAALIGN_RIGHT;
  hadc2.Init.NbrOfConversion = 5;
  hadc2.Init.DMAContinuousRequests = DISABLE;
  hadc2.Init.EOCSelection = ADC_EOC_SINGLE_CONV;
  hadc2.Init.LowPowerAutoWait = DISABLE;
  hadc2.Init.Overrun = ADC_OVR_DATA_OVERWRITTEN;
  if (HAL_ADC_Init(&hadc2) != HAL_OK)
  {
    Error_Handler();
  }

  /** Configure Regular Channel
  */
  sConfig.Channel = ADC_CHANNEL_1;
  sConfig.Rank = ADC_REGULAR_RANK_1;
  sConfig.SingleDiff = ADC_SINGLE_ENDED;
  sConfig.SamplingTime = ADC_SAMPLETIME_4CYCLES_5;
  sConfig.OffsetNumber = ADC_OFFSET_NONE;
  sConfig.Offset = 0;
  if (HAL_ADC_ConfigChannel(&hadc2, &sConfig) != HAL_OK)
  {
    Error_Handler();
  }

  /** Configure Regular Channel
  */
  sConfig.Channel = ADC_CHANNEL_2;
  sConfig.Rank = ADC_REGULAR_RANK_2;
  if (HAL_ADC_ConfigChannel(&hadc2, &sConfig) != HAL_OK)
  {
    Error_Handler();
  }

  /** Configure Regular Channel
  */
  sConfig.Channel = ADC_CHANNEL_3;
  sConfig.Rank = ADC_REGULAR_RANK_3;
  if (HAL_ADC_ConfigChannel(&hadc2, &sConfig) != HAL_OK)
  {
    Error_Handler();
  }

  /** Configure Regular Channel
  */
  sConfig.Channel = ADC_CHANNEL_4;
  sConfig.Rank = ADC_REGULAR_RANK_4;
  if (HAL_ADC_ConfigChannel(&hadc2, &sConfig) != HAL_OK)
  {
    Error_Handler();
  }

  /** Configure Regular Channel
  */
  sConfig.Channel = ADC_CHANNEL_12;
  sConfig.Rank = ADC_REGULAR_RANK_5;
  if (HAL_ADC_ConfigChannel(&hadc2, &sConfig) != HAL_OK)
  {
    Error_Handler();
  }

}

static void MX_ADC3_Init(void)
{

  ADC_MultiModeTypeDef multimode = {0};
  ADC_ChannelConfTypeDef sConfig = {0};

  /** Common config
  */
  hadc3.Instance = ADC3;
  hadc3.Init.ClockPrescaler = ADC_CLOCK_ASYNC_DIV1;
  hadc3.Init.Resolution = ADC_RESOLUTION_12B;
  hadc3.Init.ScanConvMode = ADC_SCAN_DISABLE;
  hadc3.Init.ContinuousConvMode = DISABLE;
  hadc3.Init.DiscontinuousConvMode = DISABLE;
  hadc3.Init.ExternalTrigConvEdge = ADC_EXTERNALTRIGCONVEDGE_NONE;
  hadc3.Init.ExternalTrigConv = ADC_SOFTWARE_START;
  hadc3.Init.DataAlign = ADC_DATAALIGN_RIGHT;
  hadc3.Init.NbrOfConversion = 1;
  hadc3.Init.DMAContinuousRequests = DISABLE;
  hadc3.Init.EOCSelection = ADC_EOC_SINGLE_CONV;
  hadc3.Init.LowPowerAutoWait = DISABLE;
  hadc3.Init.Overrun = ADC_OVR_DATA_OVERWRITTEN;
  if (HAL_ADC_Init(&hadc3) != HAL_OK)
  {
    Error_Handler();
  }

  /** Configure the ADC multi-mode
  */
  multimode.Mode = ADC_MODE_INDEPENDENT;
  if (HAL_ADCEx_MultiModeConfigChannel(&hadc3, &multimode) != HAL_OK)
  {
    Error_Handler();
  }

  /** Configure Regular Channel
  */
  sConfig.Channel = ADC_CHANNEL_1;
  sConfig.Rank = ADC_REGULAR_RANK_1;
  sConfig.SingleDiff = ADC_SINGLE_ENDED;
  sConfig.SamplingTime = ADC_SAMPLETIME_4CYCLES_5;
  sConfig.OffsetNumber = ADC_OFFSET_NONE;
  sConfig.Offset = 0;
  if (HAL_ADC_ConfigChannel(&hadc3, &sConfig) != HAL_OK)
  {
    Error_Handler();
  }

}

static void MX_I2C1_Init(void)
{

  hi2c1.Instance = I2C1;
  hi2c1.Init.Timing = 0x2000090E;
  hi2c1.Init.OwnAddress1 = 36;
  hi2c1.Init.AddressingMode = I2C_ADDRESSINGMODE_7BIT;
  hi2c1.Init.DualAddressMode = I2C_DUALADDRESS_DISABLE;
  hi2c1.Init.OwnAddress2 = 0;
  hi2c1.Init.OwnAddress2Masks = I2C_OA2_NOMASK;
  hi2c1.Init.GeneralCallMode = I2C_GENERALCALL_DISABLE;
  hi2c1.Init.NoStretchMode = I2C_NOSTRETCH_DISABLE;
  if (HAL_I2C_Init(&hi2c1) != HAL_OK)
  {
    Error_Handler();
  }

  /** Configure Analogue filter
  */
  if (HAL_I2CEx_ConfigAnalogFilter(&hi2c1, I2C_ANALOGFILTER_ENABLE) != HAL_OK)
  {
    Error_Handler();
  }

  /** Configure Digital filter
  */
  if (HAL_I2CEx_ConfigDigitalFilter(&hi2c1, 0) != HAL_OK)
  {
    Error_Handler();
  }

}

static void MX_RTC_Init(void)
{

  RTC_TimeTypeDef sTime = {0};
  RTC_DateTypeDef sDate = {0};

  /** Initialize RTC Only
  */
  hrtc.Instance = RTC;
  hrtc.Init.HourFormat = RTC_HOURFORMAT_24;
  hrtc.Init.AsynchPrediv = 127;
  hrtc.Init.SynchPrediv = 311;
  hrtc.Init.OutPut = RTC_OUTPUT_DISABLE;
  hrtc.Init.OutPutPolarity = RTC_OUTPUT_POLARITY_HIGH;
  hrtc.Init.OutPutType = RTC_OUTPUT_TYPE_OPENDRAIN;
  if (HAL_RTC_Init(&hrtc) != HAL_OK)
  {
    Error_Handler();
  }

  /** Initialize RTC and set the Time and Date
  */
  sTime.Hours = 0x9;
  sTime.Minutes = 0x0;
  sTime.Seconds = 0x0;
  sTime.DayLightSaving = RTC_DAYLIGHTSAVING_NONE;
  sTime.StoreOperation = RTC_STOREOPERATION_RESET;
  if (HAL_RTC_SetTime(&hrtc, &sTime, RTC_FORMAT_BCD) != HAL_OK)
  {
    Error_Handler();
  }
  sDate.WeekDay = RTC_WEEKDAY_MONDAY;
  sDate.Month = RTC_MONTH_JUNE;
  sDate.Date = 0x1;
  sDate.Year = 0x0;

  if (HAL_RTC_SetDate(&hrtc, &sDate, RTC_FORMAT_BCD) != HAL_OK)
  {
    Error_Handler();
  }

}

static void MX_TIM1_Init(void)
{

  TIM_ClockConfigTypeDef sClockSourceConfig = {0};
  TIM_MasterConfigTypeDef sMasterConfig = {0};
  TIM_OC_InitTypeDef sConfigOC = {0};
  TIM_BreakDeadTimeConfigTypeDef sBreakDeadTimeConfig = {0};

  htim1.Instance = TIM1;
  htim1.Init.Prescaler = 0;
  htim1.Init.CounterMode = TIM_COUNTERMODE_UP;
  htim1.Init.Period = 2000;
  htim1.Init.ClockDivision = TIM_CLOCKDIVISION_DIV1;
  htim1.Init.RepetitionCounter = 0;
  htim1.Init.AutoReloadPreload = TIM_AUTORELOAD_PRELOAD_ENABLE;
  if (HAL_TIM_Base_Init(&htim1) != HAL_OK)
  {
    Error_Handler();
  }
  sClockSourceConfig.ClockSource = TIM_CLOCKSOURCE_INTERNAL;
  if (HAL_TIM_ConfigClockSource(&htim1, &sClockSourceConfig) != HAL_OK)
  {
    Error_Handler();
  }
  if (HAL_TIM_PWM_Init(&htim1) != HAL_OK)
  {
    Error_Handler();
  }
  sMasterConfig.MasterOutputTrigger = TIM_TRGO_RESET;
  sMasterConfig.MasterOutputTrigger2 = TIM_TRGO2_RESET;
  sMasterConfig.MasterSlaveMode = TIM_MASTERSLAVEMODE_DISABLE;
  if (HAL_TIMEx_MasterConfigSynchronization(&htim1, &sMasterConfig) != HAL_OK)
  {
    Error_Handler();
  }
  sConfigOC.OCMode = TIM_OCMODE_PWM1;
  sConfigOC.Pulse = 1000;
  sConfigOC.OCPolarity = TIM_OCPOLARITY_HIGH;
  sConfigOC.OCNPolarity = TIM_OCNPOLARITY_HIGH;
  sConfigOC.OCFastMode = TIM_OCFAST_ENABLE;
  sConfigOC.OCIdleState = TIM_OCIDLESTATE_RESET;
  sConfigOC.OCNIdleState = TIM_OCNIDLESTATE_RESET;
  if (HAL_TIM_PWM_ConfigChannel(&htim1, &sConfigOC, TIM_CHANNEL_1) != HAL_OK)
  {
    Error_Handler();
  }
  if (HAL_TIM_PWM_ConfigChannel(&htim1, &sConfigOC, TIM_CHANNEL_2) != HAL_OK)
  {
    Error_Handler();
  }
  sBreakDeadTimeConfig.OffStateRunMode = TIM_OSSR_DISABLE;
  sBreakDeadTimeConfig.OffStateIDLEMode = TIM_OSSI_DISABLE;
  sBreakDeadTimeConfig.LockLevel = TIM_LOCKLEVEL_OFF;
  sBreakDeadTimeConfig.DeadTime = 100;
  sBreakDeadTimeConfig.BreakState = TIM_BREAK_DISABLE;
  sBreakDeadTimeConfig.BreakPolarity = TIM_BREAKPOLARITY_HIGH;
  sBreakDeadTimeConfig.BreakFilter = 0;
  sBreakDeadTimeConfig.Break2State = TIM_BREAK2_DISABLE;
  sBreakDeadTimeConfig.Break2Polarity = TIM_BREAK2POLARITY_HIGH;
  sBreakDeadTimeConfig.Break2Filter = 0;
  sBreakDeadTimeConfig.AutomaticOutput = TIM_AUTOMATICOUTPUT_DISABLE;
  if (HAL_TIMEx_ConfigBreakDeadTime(&htim1, &sBreakDeadTimeConfig) != HAL_OK)
  {
    Error_Handler();
  }
  HAL_TIM_MspPostInit(&htim1);

}

static void MX_TIM2_Init(void)
{

  TIM_ClockConfigTypeDef sClockSourceConfig = {0};
  TIM_MasterConfigTypeDef sMasterConfig = {0};
  TIM_IC_InitTypeDef sConfigIC = {0};

  htim2.Instance = TIM2;
  htim2.Init.Prescaler = 0;
  htim2.Init.CounterMode = TIM_COUNTERMODE_UP;
  htim2.Init.Period = 64000000;
  htim2.Init.ClockDivision = TIM_CLOCKDIVISION_DIV1;
  htim2.Init.AutoReloadPreload = TIM_AUTORELOAD_PRELOAD_DISABLE;
  if (HAL_TIM_Base_Init(&htim2) != HAL_OK)
  {
    Error_Handler();
  }
  sClockSourceConfig.ClockSource = TIM_CLOCKSOURCE_INTERNAL;
  if (HAL_TIM_ConfigClockSource(&htim2, &sClockSourceConfig) != HAL_OK)
  {
    Error_Handler();
  }
  if (HAL_TIM_IC_Init(&htim2) != HAL_OK)
  {
    Error_Handler();
  }
  sMasterConfig.MasterOutputTrigger = TIM_TRGO_RESET;
  sMasterConfig.MasterSlaveMode = TIM_MASTERSLAVEMODE_DISABLE;
  if (HAL_TIMEx_MasterConfigSynchronization(&htim2, &sMasterConfig) != HAL_OK)
  {
    Error_Handler();
  }
  sConfigIC.ICPolarity = TIM_INPUTCHANNELPOLARITY_RISING;
  sConfigIC.ICSelection = TIM_ICSELECTION_DIRECTTI;
  sConfigIC.ICPrescaler = TIM_ICPSC_DIV1;
  sConfigIC.ICFilter = 12;
  if (HAL_TIM_IC_ConfigChannel(&htim2, &sConfigIC, TIM_CHANNEL_1) != HAL_OK)
  {
    Error_Handler();
  }
  sConfigIC.ICPolarity = TIM_INPUTCHANNELPOLARITY_FALLING;
  sConfigIC.ICSelection = TIM_ICSELECTION_INDIRECTTI;
  sConfigIC.ICFilter = 0;
  if (HAL_TIM_IC_ConfigChannel(&htim2, &sConfigIC, TIM_CHANNEL_2) != HAL_OK)
  {
    Error_Handler();
  }

}

static void MX_TIM3_Init(void)
{

  TIM_ClockConfigTypeDef sClockSourceConfig = {0};
  TIM_MasterConfigTypeDef sMasterConfig = {0};

  htim3.Instance = TIM3;
  htim3.Init.Prescaler = 0;
  htim3.Init.CounterMode = TIM_COUNTERMODE_UP;
  htim3.Init.Period = 65535;
  htim3.Init.ClockDivision = TIM_CLOCKDIVISION_DIV1;
  htim3.Init.AutoReloadPreload = TIM_AUTORELOAD_PRELOAD_ENABLE;
  if (HAL_TIM_Base_Init(&htim3) != HAL_OK)
  {
    Error_Handler();
  }
  sClockSourceConfig.ClockSource = TIM_CLOCKSOURCE_INTERNAL;
  if (HAL_TIM_ConfigClockSource(&htim3, &sClockSourceConfig) != HAL_OK)
  {
    Error_Handler();
  }
  sMasterConfig.MasterOutputTrigger = TIM_TRGO_RESET;
  sMasterConfig.MasterSlaveMode = TIM_MASTERSLAVEMODE_DISABLE;
  if (HAL_TIMEx_MasterConfigSynchronization(&htim3, &sMasterConfig) != HAL_OK)
  {
    Error_Handler();
  }

}

static void MX_TIM8_Init(void)
{

  TIM_ClockConfigTypeDef sClockSourceConfig = {0};
  TIM_MasterConfigTypeDef sMasterConfig = {0};
  TIM_OC_InitTypeDef sConfigOC = {0};
  TIM_BreakDeadTimeConfigTypeDef sBreakDeadTimeConfig = {0};

  htim8.Instance = TIM8;
  htim8.Init.Prescaler = 0;
  htim8.Init.CounterMode = TIM_COUNTERMODE_UP;
  htim8.Init.Period = 2000;
  htim8.Init.ClockDivision = TIM_CLOCKDIVISION_DIV1;
  htim8.Init.RepetitionCounter = 0;
  htim8.Init.AutoReloadPreload = TIM_AUTORELOAD_PRELOAD_ENABLE;
  if (HAL_TIM_Base_Init(&htim8) != HAL_OK)
  {
    Error_Handler();
  }
  sClockSourceConfig.ClockSource = TIM_CLOCKSOURCE_INTERNAL;
  if (HAL_TIM_ConfigClockSource(&htim8, &sClockSourceConfig) != HAL_OK)
  {
    Error_Handler();
  }
  if (HAL_TIM_PWM_Init(&htim8) != HAL_OK)
  {
    Error_Handler();
  }
  sMasterConfig.MasterOutputTrigger = TIM_TRGO_RESET;
  sMasterConfig.MasterOutputTrigger2 = TIM_TRGO2_RESET;
  sMasterConfig.MasterSlaveMode = TIM_MASTERSLAVEMODE_DISABLE;
  if (HAL_TIMEx_MasterConfigSynchronization(&htim8, &sMasterConfig) != HAL_OK)
  {
    Error_Handler();
  }
  sConfigOC.OCMode = TIM_OCMODE_PWM1;
  sConfigOC.Pulse = 1000;
  sConfigOC.OCPolarity = TIM_OCPOLARITY_HIGH;
  sConfigOC.OCNPolarity = TIM_OCNPOLARITY_HIGH;
  sConfigOC.OCFastMode = TIM_OCFAST_DISABLE;
  sConfigOC.OCIdleState = TIM_OCIDLESTATE_RESET;
  sConfigOC.OCNIdleState = TIM_OCNIDLESTATE_RESET;
  if (HAL_TIM_PWM_ConfigChannel(&htim8, &sConfigOC, TIM_CHANNEL_1) != HAL_OK)
  {
    Error_Handler();
  }
  sBreakDeadTimeConfig.OffStateRunMode = TIM_OSSR_DISABLE;
  sBreakDeadTimeConfig.OffStateIDLEMode = TIM_OSSI_DISABLE;
  sBreakDeadTimeConfig.LockLevel = TIM_LOCKLEVEL_OFF;
  sBreakDeadTimeConfig.DeadTime = 100;
  sBreakDeadTimeConfig.BreakState = TIM_BREAK_DISABLE;
  sBreakDeadTimeConfig.BreakPolarity = TIM_BREAKPOLARITY_HIGH;
  sBreakDeadTimeConfig.BreakFilter = 0;
  sBreakDeadTimeConfig.Break2State = TIM_BREAK2_DISABLE;
  sBreakDeadTimeConfig.Break2Polarity = TIM_BREAK2POLARITY_HIGH;
  sBreakDeadTimeConfig.Break2Filter = 0;
  sBreakDeadTimeConfig.AutomaticOutput = TIM_AUTOMATICOUTPUT_DISABLE;
  if (HAL_TIMEx_ConfigBreakDeadTime(&htim8, &sBreakDeadTimeConfig) != HAL_OK)
  {
    Error_Handler();
  }
  HAL_TIM_MspPostInit(&htim8);

}

static void MX_TIM15_Init(void)
{

  TIM_ClockConfigTypeDef sClockSourceConfig = {0};
  TIM_MasterConfigTypeDef sMasterConfig = {0};
  TIM_OC_InitTypeDef sConfigOC = {0};
  TIM_BreakDeadTimeConfigTypeDef sBreakDeadTimeConfig = {0};

  htim15.Instance = TIM15;
  htim15.Init.Prescaler = 0;
  htim15.Init.CounterMode = TIM_COUNTERMODE_UP;
  htim15.Init.Period = 2000;
  htim15.Init.ClockDivision = TIM_CLOCKDIVISION_DIV1;
  htim15.Init.RepetitionCounter = 0;
  htim15.Init.AutoReloadPreload = TIM_AUTORELOAD_PRELOAD_ENABLE;
  if (HAL_TIM_Base_Init(&htim15) != HAL_OK)
  {
    Error_Handler();
  }
  sClockSourceConfig.ClockSource = TIM_CLOCKSOURCE_INTERNAL;
  if (HAL_TIM_ConfigClockSource(&htim15, &sClockSourceConfig) != HAL_OK)
  {
    Error_Handler();
  }
  if (HAL_TIM_PWM_Init(&htim15) != HAL_OK)
  {
    Error_Handler();
  }
  sMasterConfig.MasterOutputTrigger = TIM_TRGO_RESET;
  sMasterConfig.MasterSlaveMode = TIM_MASTERSLAVEMODE_DISABLE;
  if (HAL_TIMEx_MasterConfigSynchronization(&htim15, &sMasterConfig) != HAL_OK)
  {
    Error_Handler();
  }
  sConfigOC.OCMode = TIM_OCMODE_PWM1;
  sConfigOC.Pulse = 1000;
  sConfigOC.OCPolarity = TIM_OCPOLARITY_HIGH;
  sConfigOC.OCNPolarity = TIM_OCNPOLARITY_HIGH;
  sConfigOC.OCFastMode = TIM_OCFAST_DISABLE;
  sConfigOC.OCIdleState = TIM_OCIDLESTATE_RESET;
  sConfigOC.OCNIdleState = TIM_OCNIDLESTATE_RESET;
  if (HAL_TIM_PWM_ConfigChannel(&htim15, &sConfigOC, TIM_CHANNEL_1) != HAL_OK)
  {
    Error_Handler();
  }
  sBreakDeadTimeConfig.OffStateRunMode = TIM_OSSR_DISABLE;
  sBreakDeadTimeConfig.OffStateIDLEMode = TIM_OSSI_DISABLE;
  sBreakDeadTimeConfig.LockLevel = TIM_LOCKLEVEL_OFF;
  sBreakDeadTimeConfig.DeadTime = 100;
  sBreakDeadTimeConfig.BreakState = TIM_BREAK_DISABLE;
  sBreakDeadTimeConfig.BreakPolarity = TIM_BREAKPOLARITY_HIGH;
  sBreakDeadTimeConfig.BreakFilter = 0;
  sBreakDeadTimeConfig.AutomaticOutput = TIM_AUTOMATICOUTPUT_DISABLE;
  if (HAL_TIMEx_ConfigBreakDeadTime(&htim15, &sBreakDeadTimeConfig) != HAL_OK)
  {
    Error_Handler();
  }
  HAL_TIM_MspPostInit(&htim15);

}

static void MX_USART1_UART_Init(void)
{

  huart1.Instance = USART1;
  huart1.Init.BaudRate = 9600;
  huart1.Init.WordLength = UART_WORDLENGTH_8B;
  huart1.Init.StopBits = UART_STOPBITS_1;
  huart1.Init.Parity = UART_PARITY_NONE;
  huart1.Init.Mode = UART_MODE_TX_RX;
  huart1.Init.HwFlowCtl = UART_HWCONTROL_NONE;
  huart1.Init.OverSampling = UART_OVERSAMPLING_16;
  huart1.Init.OneBitSampling = UART_ONE_BIT_SAMPLE_DISABLE;
  huart1.AdvancedInit.AdvFeatureInit = UART_ADVFEATURE_NO_INIT;
  if (HAL_UART_Init(&huart1) != HAL_OK)
  {
    Error_Handler();
  }

}

static void MX_USART2_UART_Init(void)
{

  huart2.Instance = USART2;
  huart2.Init.BaudRate = 230400;
  huart2.Init.WordLength = UART_WORDLENGTH_8B;
  huart2.Init.StopBits = UART_STOPBITS_1;
  huart2.Init.Parity = UART_PARITY_NONE;
  huart2.Init.Mode = UART_MODE_TX_RX;
  huart2.Init.HwFlowCtl = UART_HWCONTROL_NONE;
  huart2.Init.OverSampling = UART_OVERSAMPLING_16;
  huart2.Init.OneBitSampling = UART_ONE_BIT_SAMPLE_DISABLE;
  huart2.AdvancedInit.AdvFeatureInit = UART_ADVFEATURE_NO_INIT;
  if (HAL_UART_Init(&huart2) != HAL_OK)
  {
    Error_Handler();
  }

}

static void MX_DMA_Init(void)
{

  /* DMA controller clock enable */
  __HAL_RCC_DMA2_CLK_ENABLE();
  __HAL_RCC_DMA1_CLK_ENABLE();

  /* DMA interrupt init */
  /* DMA1_Channel6_IRQn interrupt configuration */
  HAL_NVIC_SetPriority(DMA1_Channel6_IRQn, 0, 0);
  HAL_NVIC_EnableIRQ(DMA1_Channel6_IRQn);
  /* DMA1_Channel7_IRQn interrupt configuration */
  HAL_NVIC_SetPriority(DMA1_Channel7_IRQn, 0, 0);
  HAL_NVIC_EnableIRQ(DMA1_Channel7_IRQn);
  /* DMA2_Channel1_IRQn interrupt configuration */
  HAL_NVIC_SetPriority(DMA2_Channel1_IRQn, 0, 0);
  HAL_NVIC_EnableIRQ(DMA2_Channel1_IRQn);

}

static void MX_GPIO_Init(void)
{
  GPIO_InitTypeDef GPIO_InitStruct = {0};

  /* GPIO Ports Clock Enable */
  __HAL_RCC_GPIOC_CLK_ENABLE();
  __HAL_RCC_GPIOF_CLK_ENABLE();
  __HAL_RCC_GPIOA_CLK_ENABLE();
  __HAL_RCC_GPIOB_CLK_ENABLE();

  /*Configure GPIO pin Output Level */
  HAL_GPIO_WritePin(LED_1_GPIO_Port, LED_1_Pin, GPIO_PIN_RESET);

  /*Configure GPIO pin Output Level */
  HAL_GPIO_WritePin(GPIOF, LED_2_Pin|LED_3_Pin, GPIO_PIN_RESET);

  /*Configure GPIO pin Output Level */
  HAL_GPIO_WritePin(GPIOB, Port_2_Pin|Port_1_Pin|Port_3_Pin|Port_4_Pin, GPIO_PIN_RESET);

  /*Configure GPIO pin Output Level */
  HAL_GPIO_WritePin(Direct_GPIO_Port, Direct_Pin, GPIO_PIN_RESET);

  /*Configure GPIO pins : START_Pin STOP_Pin */
  GPIO_InitStruct.Pin = START_Pin|STOP_Pin;
  GPIO_InitStruct.Mode = GPIO_MODE_IT_RISING_FALLING;
  GPIO_InitStruct.Pull = GPIO_NOPULL;
  HAL_GPIO_Init(GPIOC, &GPIO_InitStruct);

  /*Configure GPIO pin : LED_1_Pin */
  GPIO_InitStruct.Pin = LED_1_Pin;
  GPIO_InitStruct.Mode = GPIO_MODE_OUTPUT_PP;
  GPIO_InitStruct.Pull = GPIO_NOPULL;
  GPIO_InitStruct.Speed = GPIO_SPEED_FREQ_LOW;
  HAL_GPIO_Init(LED_1_GPIO_Port, &GPIO_InitStruct);

  /*Configure GPIO pins : LED_2_Pin LED_3_Pin */
  GPIO_InitStruct.Pin = LED_2_Pin|LED_3_Pin;
  GPIO_InitStruct.Mode = GPIO_MODE_OUTPUT_PP;
  GPIO_InitStruct.Pull = GPIO_NOPULL;
  GPIO_InitStruct.Speed = GPIO_SPEED_FREQ_LOW;
  HAL_GPIO_Init(GPIOF, &GPIO_InitStruct);

  /*Configure GPIO pin : INT_Pin */
  GPIO_InitStruct.Pin = INT_Pin;
  GPIO_InitStruct.Mode = GPIO_MODE_IT_RISING_FALLING;
  GPIO_InitStruct.Pull = GPIO_NOPULL;
  HAL_GPIO_Init(INT_GPIO_Port, &GPIO_InitStruct);

  /*Configure GPIO pins : Port_2_Pin Port_1_Pin Port_3_Pin Port_4_Pin */
  GPIO_InitStruct.Pin = Port_2_Pin|Port_1_Pin|Port_3_Pin|Port_4_Pin;
  GPIO_InitStruct.Mode = GPIO_MODE_OUTPUT_PP;
  GPIO_InitStruct.Pull = GPIO_NOPULL;
  GPIO_InitStruct.Speed = GPIO_SPEED_FREQ_LOW;
  HAL_GPIO_Init(GPIOB, &GPIO_InitStruct);

  /*Configure GPIO pin : Direct_Pin */
  GPIO_InitStruct.Pin = Direct_Pin;
  GPIO_InitStruct.Mode = GPIO_MODE_OUTPUT_PP;
  GPIO_InitStruct.Pull = GPIO_NOPULL;
  GPIO_InitStruct.Speed = GPIO_SPEED_FREQ_LOW;
  HAL_GPIO_Init(Direct_GPIO_Port, &GPIO_InitStruct);

  /*Configure GPIO pin : PB5 */
  GPIO_InitStruct.Pin = GPIO_PIN_5;
  GPIO_InitStruct.Mode = GPIO_MODE_IT_RISING_FALLING;
  GPIO_InitStruct.Pull = GPIO_NOPULL;
  HAL_GPIO_Init(GPIOB, &GPIO_InitStruct);

  /* EXTI interrupt init*/
  HAL_NVIC_SetPriority(EXTI1_IRQn, 0, 0);
  HAL_NVIC_EnableIRQ(EXTI1_IRQn);

  HAL_NVIC_SetPriority(EXTI9_5_IRQn, 1, 0);
  HAL_NVIC_EnableIRQ(EXTI9_5_IRQn);

  HAL_NVIC_SetPriority(EXTI15_10_IRQn, 3, 0);
  HAL_NVIC_EnableIRQ(EXTI15_10_IRQn);

}

/* USER CODE BEGIN 4 */

void HAL_TIM_IC_CaptureCallback(TIM_HandleTypeDef *htim)
{
    if (htim->Instance == TIM2)
    {
        if(htim->Channel == HAL_TIM_ACTIVE_CHANNEL_1)
        {

        //	 TIM3->CNT=0;
        	 HAL_TIM_PWM_Stop(&htim1, TIM_CHANNEL_1);
        	 HAL_TIM_PWM_Stop(&htim1, TIM_CHANNEL_2);
        	 HAL_TIM_PWM_Stop(&htim8, TIM_CHANNEL_1);
        	 HAL_TIM_PWM_Stop(&htim15, TIM_CHANNEL_1);

        	 period = 0;

            TIM2->CNT = 0;
            period = HAL_TIM_ReadCapturedValue(&htim2, TIM_CHANNEL_1);
            pulseWidth = HAL_TIM_ReadCapturedValue(&htim2, TIM_CHANNEL_2);

            rpm= 480000000/period;
            f=32000000/period;

            HAL_TIMEx_PWMN_Start(&htim1, TIM_CHANNEL_1);
            HAL_TIMEx_PWMN_Start(&htim1, TIM_CHANNEL_2);
            HAL_TIMEx_PWMN_Start(&htim8, TIM_CHANNEL_1);
            HAL_TIMEx_PWMN_Start(&htim15, TIM_CHANNEL_1);

        }

        if(htim->Channel == HAL_TIM_ACTIVE_CHANNEL_2)
                {

        	//  TIM3->CNT=0;
        	  HAL_GPIO_TogglePin(GPIOC, GPIO_PIN_15);

        	  HAL_TIMEx_PWMN_Stop(&htim1, TIM_CHANNEL_1);
        	  HAL_TIMEx_PWMN_Stop(&htim1, TIM_CHANNEL_2);
        	  HAL_TIMEx_PWMN_Stop(&htim8, TIM_CHANNEL_1);
        	  HAL_TIMEx_PWMN_Stop(&htim15, TIM_CHANNEL_1);

        	  HAL_TIM_PWM_Start(&htim1, TIM_CHANNEL_1);
        	  HAL_TIM_PWM_Start(&htim1, TIM_CHANNEL_2);
        	  HAL_TIM_PWM_Start(&htim8, TIM_CHANNEL_1);
        	  HAL_TIM_PWM_Start(&htim15, TIM_CHANNEL_1);
                                                         }

    }
}

void HAL_GPIO_EXTI_Callback(uint16_t GPIO_Pin)
{
   if(GPIO_Pin == GPIO_PIN_13) // если прерывание поступило от ножки PC13
   {
      // Переключение в противоположное состояние ножки
      // выхода для управления светодиодом (LED):
      HAL_GPIO_TogglePin(GPIOC, GPIO_PIN_15);
      if (GPIO_PIN_RESET == HAL_GPIO_ReadPin (GPIOC, GPIO_PIN_13)){

            if((pwm_cmd>=0)&&(pwm_cmd<=19)&&(status==0)){

            	HAL_RTC_GetTime(&hrtc, &sTime, RTC_FORMAT_BIN); // RTC_FORMAT_BIN , RTC_FORMAT_BCD
            	HAL_RTC_GetDate(&hrtc, &sDate, RTC_FORMAT_BIN);

            	hour=sTime.Hours;
            	min=sTime.Minutes;
            	sec=sTime.Seconds;

            	status=1;
            }

        		   pwm_cmd=pwm_cmd+10;
        		   if(pwm_cmd>=1999){pwm_cmd=2000;}
        		   pwm_tgr=4;

        		   EXTI->PR = EXTI_PR_PR13;
        	   }

   }

   if(GPIO_Pin == GPIO_PIN_14) // если прерывание поступило от ножки PC14
     {

	   if (GPIO_PIN_SET == HAL_GPIO_ReadPin (GPIOC, GPIO_PIN_14)){
        // Переключение в противоположное состояние ножки
        // выхода для управления светодиодом (LED):
        HAL_GPIO_TogglePin(GPIOC, GPIO_PIN_15);}
	   if (GPIO_PIN_RESET == HAL_GPIO_ReadPin (GPIOC, GPIO_PIN_14)){

		   if((pwm_cmd==0)&&(status==1)){
		              	status=0;

		              	hour=0;
		              	min=0;
		              	sec=0;
		              }

		   pwm_cmd=pwm_cmd-10;
		   if(pwm_cmd>=2100){pwm_cmd=0;}
		   if(pwm_cmd<=1){pwm_cmd=0;}
		   pwm_tgr=4;
		   EXTI->PR = EXTI_PR_PR14;
	   }

     }

   if(GPIO_Pin == GPIO_PIN_5) // если прерывание поступило от ножки PB_5
      {
	   if (GPIO_PIN_SET == HAL_GPIO_ReadPin (GPIOB, GPIO_PIN_5)){
	             LED_3_OFF;

	   			// if(page_num>2){page_num=0;}
	   			// page_flag=0;
	   		  EXTI->PR = EXTI_PR_PR5;
      }

     if (GPIO_PIN_RESET == HAL_GPIO_ReadPin (GPIOB, GPIO_PIN_5)){

    	         LED_3_ON;
    	 	     page_flag=1;
    	         page_num++;
    	         if(page_num>2){page_num=0;}
    	         EXTI->PR = EXTI_PR_PR5;

     }

}
}

void HAL_UART_TxCpltCallback(UART_HandleTypeDef *huart)

{

RX_2;

//LED_3_OFF;
}

void HAL_ADC_ConvCpltCallback(ADC_HandleTypeDef* hadc)
{
    if(hadc->Instance == ADC2)
    {
        flag = 1;
    }
}
/* USER CODE END 4 */

void Error_Handler(void)
{
  __disable_irq();
  while (1)
  {
  }
}
